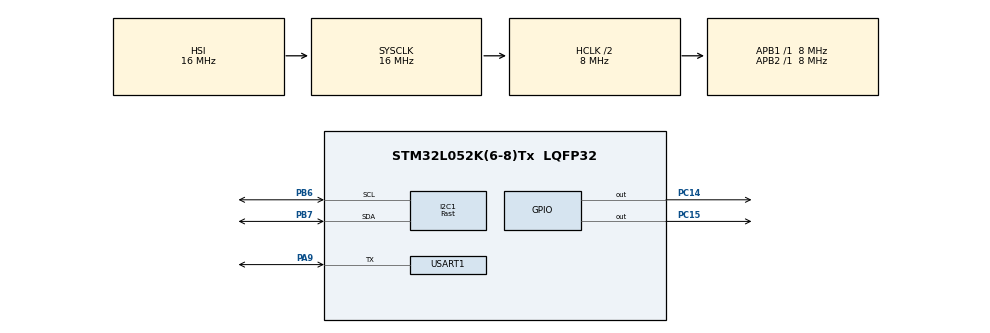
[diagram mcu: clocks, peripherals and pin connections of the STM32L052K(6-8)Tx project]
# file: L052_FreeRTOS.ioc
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FREERTOS.Tasks01=defaultTask,0,128,defaultTask_Init,Default,NULL,Dynamic,NULL,NULL;ScreenTask,-2,128,ScreenTask_Init,Default,NULL,Dynamic,NULL,NULL;LinTask,3,128,LinTask_Init,Default,NULL,Dynamic,NULL,NULL
FREERTOS.configMAX_TASK_NAME_LEN=255
FREERTOS.configTOTAL_HEAP_SIZE=2504
I2C1.I2C_Speed_Mode=I2C_Fast
I2C1.Timing=0x0010020A
Mcu.Family=STM32L0
Mcu.Name=STM32L052K(6-8)Tx
Mcu.Package=LQFP32
NVIC.TIM2_IRQn=true\:3\:0\:false\:false\:true\:false\:false\:true\:true
NVIC.TimeBase=TIM2_IRQn
NVIC.TimeBaseIP=TIM2
NVIC.USART1_IRQn=true\:3\:0\:false\:false\:true\:true\:true\:true\:true
PA13.Mode=Serial_Wire
PA13.Signal=SYS_SWDIO
PA14.Mode=Serial_Wire
PA14.Signal=SYS_SWCLK
PA9.Mode=Half_duplex(single_wire_mode)
PA9.Signal=USART1_TX
PB6.Mode=I2C
PB6.Signal=I2C1_SCL
PB7.Mode=I2C
PB7.Signal=I2C1_SDA
PC14-OSC32_IN.Signal=GPIO_Output
PC15-OSC32_OUT.Signal=GPIO_Output
ProjectManager.HeapSize=0x200
ProjectManager.StackSize=0x400
ProjectManager.TargetToolchain=STM32CubeIDE
RCC.AHBCLKDivider=RCC_SYSCLK_DIV2
RCC.AHBFreq_Value=8000000
RCC.APB1Freq_Value=8000000
RCC.APB1TimFreq_Value=8000000
RCC.APB2Freq_Value=8000000
RCC.APB2TimFreq_Value=8000000
RCC.HCLKFreq_Value=8000000
RCC.HSI16_VALUE=16000000
RCC.HSI48_VALUE=48000000
RCC.HSI_VALUE=16000000
RCC.LSE_VALUE=32768
RCC.MSI_VALUE=2097000
RCC.SYSCLKFreq_VALUE=16000000
RCC.SYSCLKSource=RCC_SYSCLKSOURCE_HSI
RCC.VCOOutputFreq_Value=48000000
USART1.BaudRate=9600
USART1.VirtualMode-Half_duplex(single_wire_mode)=VM_ASYNC
VP_FREERTOS_VS_CMSIS_V1.Mode=CMSIS_V1
VP_SYS_VS_tim2.Mode=TIM2
board=custom

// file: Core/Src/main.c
/* USER CODE BEGIN Header */
/**
 ******************************************************************************
 * @file           : main.c
 * @brief          : Main program body
 ******************************************************************************
 * @attention
 *
 * Copyright (c) 2024 STMicroelectronics.
 * All rights reserved.
 *
 * This software is licensed under terms that can be found in the LICENSE file
 * in the root directory of this software component.
 * If no LICENSE file comes with this software, it is provided AS-IS.
 *
 ******************************************************************************
 */
/* USER CODE END Header */
#include "main.h"
#include "cmsis_os.h"

/* USER CODE BEGIN Includes */
#include "usr_screen.h"
#include "usr_lin.h"
/* USER CODE END Includes */

I2C_HandleTypeDef hi2c1;

UART_HandleTypeDef huart1;

osThreadId defaultTaskHandle;
osThreadId ScreenTaskHandle;
osThreadId LinTaskHandle;

void SystemClock_Config(void);
static void MX_GPIO_Init(void);
static void MX_I2C1_Init(void);
static void MX_USART1_UART_Init(void);
void defaultTask_Init(void const * argument);
void ScreenTask_Init(void const * argument);
void LinTask_Init(void const * argument);

int main(void)
{

  /* MCU Configuration--------------------------------------------------------*/

  /* Reset of all peripherals, Initializes the Flash interface and the Systick. */
  HAL_Init();

  /* Configure the system clock */
  SystemClock_Config();

  /* Initialize all configured peripherals */
  MX_GPIO_Init();
  MX_I2C1_Init();
  MX_USART1_UART_Init();

  /* Create the thread(s) */
  /* definition and creation of defaultTask */
  //osThreadDef(defaultTask, defaultTask_Init, osPriorityNormal, 0, 128);
  //defaultTaskHandle = osThreadCreate(osThread(defaultTask), NULL);

  /* definition and creation of ScreenTask */
  osThreadDef(ScreenTask, ScreenTask_Init, osPriorityLow, 0, 128);
  ScreenTaskHandle = osThreadCreate(osThread(ScreenTask), NULL);

  /* definition and creation of LinTask */
  osThreadDef(LinTask, LinTask_Init, osPriorityLow, 0, 128);
  LinTaskHandle = osThreadCreate(osThread(LinTask), NULL);

  /* Start scheduler */
  osKernelStart();

  /* We should never get here as control is now taken by the scheduler */

  /* Infinite loop */
	while (1) {

	}
}

void SystemClock_Config(void)
{
  RCC_OscInitTypeDef RCC_OscInitStruct = {0};
  RCC_ClkInitTypeDef RCC_ClkInitStruct = {0};
  RCC_PeriphCLKInitTypeDef PeriphClkInit = {0};

  /** Configure the main internal regulator output voltage
  */
  __HAL_PWR_VOLTAGESCALING_CONFIG(PWR_REGULATOR_VOLTAGE_SCALE1);

  /** Initializes the RCC Oscillators according to the specified parameters
  * in the RCC_OscInitTypeDef structure.
  */
  RCC_OscInitStruct.OscillatorType = RCC_OSCILLATORTYPE_HSI;
  RCC_OscInitStruct.HSIState = RCC_HSI_ON;
  RCC_OscInitStruct.HSICalibrationValue = RCC_HSICALIBRATION_DEFAULT;
  RCC_OscInitStruct.PLL.PLLState = RCC_PLL_NONE;
  if (HAL_RCC_OscConfig(&RCC_OscInitStruct) != HAL_OK)
  {
    Error_Handler();
  }

  /** Initializes the CPU, AHB and APB buses clocks
  */
  RCC_ClkInitStruct.ClockType = RCC_CLOCKTYPE_HCLK|RCC_CLOCKTYPE_SYSCLK
                              |RCC_CLOCKTYPE_PCLK1|RCC_CLOCKTYPE_PCLK2;
  RCC_ClkInitStruct.SYSCLKSource = RCC_SYSCLKSOURCE_HSI;
  RCC_ClkInitStruct.AHBCLKDivider = RCC_SYSCLK_DIV2;
  RCC_ClkInitStruct.APB1CLKDivider = RCC_HCLK_DIV1;
  RCC_ClkInitStruct.APB2CLKDivider = RCC_HCLK_DIV1;

  if (HAL_RCC_ClockConfig(&RCC_ClkInitStruct, FLASH_LATENCY_0) != HAL_OK)
  {
    Error_Handler();
  }
  PeriphClkInit.PeriphClockSelection = RCC_PERIPHCLK_USART1|RCC_PERIPHCLK_I2C1;
  PeriphClkInit.Usart1ClockSelection = RCC_USART1CLKSOURCE_PCLK2;
  PeriphClkInit.I2c1ClockSelection = RCC_I2C1CLKSOURCE_PCLK1;
  if (HAL_RCCEx_PeriphCLKConfig(&PeriphClkInit) != HAL_OK)
  {
    Error_Handler();
  }
}

static void MX_I2C1_Init(void)
{

  hi2c1.Instance = I2C1;
  hi2c1.Init.Timing = 0x0010020A;
  hi2c1.Init.OwnAddress1 = 0;
  hi2c1.Init.AddressingMode = I2C_ADDRESSINGMODE_7BIT;
  hi2c1.Init.DualAddressMode = I2C_DUALADDRESS_DISABLE;
  hi2c1.Init.OwnAddress2 = 0;
  hi2c1.Init.OwnAddress2Masks = I2C_OA2_NOMASK;
  hi2c1.Init.GeneralCallMode = I2C_GENERALCALL_DISABLE;
  hi2c1.Init.NoStretchMode = I2C_NOSTRETCH_DISABLE;
  if (HAL_I2C_Init(&hi2c1) != HAL_OK)
  {
    Error_Handler();
  }

  /** Configure Analogue filter
  */
  if (HAL_I2CEx_ConfigAnalogFilter(&hi2c1, I2C_ANALOGFILTER_ENABLE) != HAL_OK)
  {
    Error_Handler();
  }

  /** Configure Digital filter
  */
  if (HAL_I2CEx_ConfigDigitalFilter(&hi2c1, 0) != HAL_OK)
  {
    Error_Handler();
  }

}

static void MX_USART1_UART_Init(void)
{

  huart1.Instance = USART1;
  huart1.Init.BaudRate = 9600;
  huart1.Init.WordLength = UART_WORDLENGTH_8B;
  huart1.Init.StopBits = UART_STOPBITS_1;
  huart1.Init.Parity = UART_PARITY_NONE;
  huart1.Init.Mode = UART_MODE_TX_RX;
  huart1.Init.HwFlowCtl = UART_HWCONTROL_NONE;
  huart1.Init.OverSampling = UART_OVERSAMPLING_16;
  huart1.Init.OneBitSampling = UART_ONE_BIT_SAMPLE_DISABLE;
  huart1.AdvancedInit.AdvFeatureInit = UART_ADVFEATURE_NO_INIT;
  if (HAL_HalfDuplex_Init(&huart1) != HAL_OK)
  {
    Error_Handler();
  }
  /* USER CODE BEGIN USART1_Init 2 */
	// Enable the IDLE line detection interrupt
	    __HAL_UART_ENABLE_IT(&huart1, UART_IT_IDLE);
  /* USER CODE END USART1_Init 2 */

}

static void MX_GPIO_Init(void)
{
  GPIO_InitTypeDef GPIO_InitStruct = {0};

  /* GPIO Ports Clock Enable */
  __HAL_RCC_GPIOC_CLK_ENABLE();
  __HAL_RCC_GPIOA_CLK_ENABLE();
  __HAL_RCC_GPIOB_CLK_ENABLE();

  /*Configure GPIO pin Output Level */
  HAL_GPIO_WritePin(GPIOC, GPIO_PIN_14|GPIO_PIN_15, GPIO_PIN_RESET);

  /*Configure GPIO pins : PC14 PC15 */
  GPIO_InitStruct.Pin = GPIO_PIN_14|GPIO_PIN_15;
  GPIO_InitStruct.Mode = GPIO_MODE_OUTPUT_PP;
  GPIO_InitStruct.Pull = GPIO_NOPULL;
  GPIO_InitStruct.Speed = GPIO_SPEED_FREQ_LOW;
  HAL_GPIO_Init(GPIOC, &GPIO_InitStruct);

}

void defaultTask_Init(void const * argument)
{
	for (;;) {
		osDelay(1);
	}
}

void ScreenTask_Init(void const * argument)
{
  /* USER CODE BEGIN ScreenTask_Init */

	ScreenInit();
	/* Infinite loop */
	for (;;) {
		ScreenLoop();
		osDelay(1);
	}
  /* USER CODE END ScreenTask_Init */
}

void LinTask_Init(void const * argument)
{
  /* USER CODE BEGIN LinTask_Init */

	HAL_HalfDuplex_EnableReceiver(&huart1);
	HAL_UART_Receive_IT(&huart1, &g_LinSingleMsg, 1);

	/* Infinite loop */
	for (;;) {
		LinLoop();
		//osDelay(1);
	}
  /* USER CODE END LinTask_Init */
}

void HAL_TIM_PeriodElapsedCallback(TIM_HandleTypeDef *htim)
{
  if (htim->Instance == TIM2) {
    HAL_IncTick();
  }
}

void Error_Handler(void)
{
	__disable_irq();
	while (1) {
	}
}
